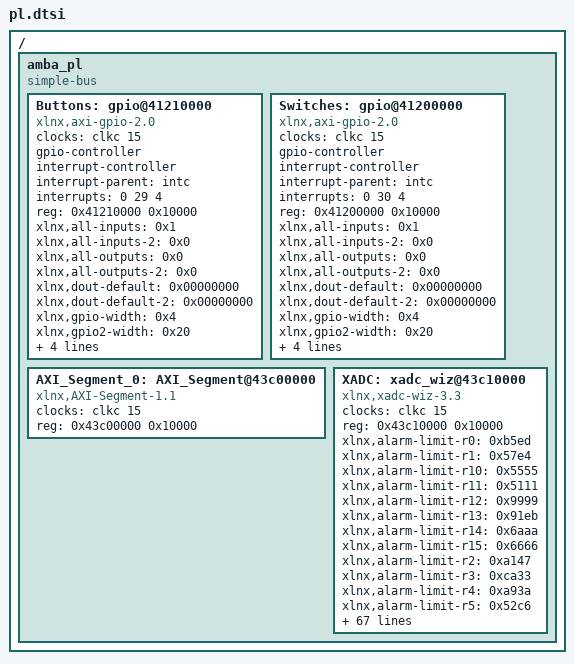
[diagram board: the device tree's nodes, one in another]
/*
 * CAUTION: This file is automatically generated by Xilinx.
 * Version:  
 * Today is: Sat Jan 26 14:19:15 2019
 */


/ {
	amba_pl: amba_pl {
		#address-cells = <1>;
		#size-cells = <1>;
		compatible = "simple-bus";
		ranges ;
		Buttons: gpio@41210000 {
			#gpio-cells = <3>;
			#interrupt-cells = <2>;
			clock-names = "s_axi_aclk";
			clocks = <&clkc 15>;
			compatible = "xlnx,axi-gpio-2.0", "xlnx,xps-gpio-1.00.a";
			gpio-controller ;
			interrupt-controller ;
			interrupt-names = "ip2intc_irpt";
			interrupt-parent = <&intc>;
			interrupts = <0 29 4>;
			reg = <0x41210000 0x10000>;
			xlnx,all-inputs = <0x1>;
			xlnx,all-inputs-2 = <0x0>;
			xlnx,all-outputs = <0x0>;
			xlnx,all-outputs-2 = <0x0>;
			xlnx,dout-default = <0x00000000>;
			xlnx,dout-default-2 = <0x00000000>;
			xlnx,gpio-width = <0x4>;
			xlnx,gpio2-width = <0x20>;
			xlnx,interrupt-present = <0x1>;
			xlnx,is-dual = <0x0>;
			xlnx,tri-default = <0xFFFFFFFF>;
			xlnx,tri-default-2 = <0xFFFFFFFF>;
		};
		Switches: gpio@41200000 {
			#gpio-cells = <3>;
			#interrupt-cells = <2>;
			clock-names = "s_axi_aclk";
			clocks = <&clkc 15>;
			compatible = "xlnx,axi-gpio-2.0", "xlnx,xps-gpio-1.00.a";
			gpio-controller ;
			interrupt-controller ;
			interrupt-names = "ip2intc_irpt";
			interrupt-parent = <&intc>;
			interrupts = <0 30 4>;
			reg = <0x41200000 0x10000>;
			xlnx,all-inputs = <0x1>;
			xlnx,all-inputs-2 = <0x0>;
			xlnx,all-outputs = <0x0>;
			xlnx,all-outputs-2 = <0x0>;
			xlnx,dout-default = <0x00000000>;
			xlnx,dout-default-2 = <0x00000000>;
			xlnx,gpio-width = <0x4>;
			xlnx,gpio2-width = <0x20>;
			xlnx,interrupt-present = <0x1>;
			xlnx,is-dual = <0x0>;
			xlnx,tri-default = <0xFFFFFFFF>;
			xlnx,tri-default-2 = <0xFFFFFFFF>;
		};
		AXI_Segment_0: AXI_Segment@43c00000 {
			clock-names = "s_axi_aclk";
			clocks = <&clkc 15>;
			compatible = "xlnx,AXI-Segment-1.1";
			reg = <0x43c00000 0x10000>;
		};
		XADC: xadc_wiz@43c10000 {
			clock-names = "s_axi_aclk";
			clocks = <&clkc 15>;
			compatible = "xlnx,xadc-wiz-3.3", "xlnx,axi-xadc-1.00.a";
			reg = <0x43c10000 0x10000>;
			xlnx,alarm-limit-r0 = <0xb5ed>;
			xlnx,alarm-limit-r1 = <0x57e4>;
			xlnx,alarm-limit-r10 = <0x5555>;
			xlnx,alarm-limit-r11 = <0x5111>;
			xlnx,alarm-limit-r12 = <0x9999>;
			xlnx,alarm-limit-r13 = <0x91eb>;
			xlnx,alarm-limit-r14 = <0x6aaa>;
			xlnx,alarm-limit-r15 = <0x6666>;
			xlnx,alarm-limit-r2 = <0xa147>;
			xlnx,alarm-limit-r3 = <0xca33>;
			xlnx,alarm-limit-r4 = <0xa93a>;
			xlnx,alarm-limit-r5 = <0x52c6>;
			xlnx,alarm-limit-r6 = <0x9555>;
			xlnx,alarm-limit-r7 = <0xae4e>;
			xlnx,alarm-limit-r8 = <0x5999>;
			xlnx,alarm-limit-r9 = <0x5111>;
			xlnx,configuration-r0 = <0x0>;
			xlnx,configuration-r1 = <0x21a0>;
			xlnx,configuration-r2 = <0x400>;
			xlnx,dclk-frequency = <0x64>;
			xlnx,external-mux = "none";
			xlnx,external-mux-channel = "VP_VN";
			xlnx,external-muxaddr-enable = <0x0>;
			xlnx,fifo-depth = <0x7>;
			xlnx,has-axi = <0x1>;
			xlnx,has-axi4stream = <0x0>;
			xlnx,has-busy = <0x1>;
			xlnx,has-channel = <0x1>;
			xlnx,has-convst = <0x0>;
			xlnx,has-convstclk = <0x0>;
			xlnx,has-dclk = <0x1>;
			xlnx,has-drp = <0x0>;
			xlnx,has-eoc = <0x1>;
			xlnx,has-eos = <0x1>;
			xlnx,has-external-mux = <0x0>;
			xlnx,has-jtagbusy = <0x0>;
			xlnx,has-jtaglocked = <0x0>;
			xlnx,has-jtagmodified = <0x0>;
			xlnx,has-ot-alarm = <0x1>;
			xlnx,has-reset = <0x0>;
			xlnx,has-temp-bus = <0x0>;
			xlnx,has-user-temp-alarm = <0x1>;
			xlnx,has-vbram-alarm = <0x0>;
			xlnx,has-vccaux-alarm = <0x1>;
			xlnx,has-vccddro-alarm = <0x1>;
			xlnx,has-vccint-alarm = <0x1>;
			xlnx,has-vccpaux-alarm = <0x1>;
			xlnx,has-vccpint-alarm = <0x1>;
			xlnx,has-vn = <0x1>;
			xlnx,has-vp = <0x1>;
			xlnx,include-intr = <0x1>;
			xlnx,sampling-rate = "961538.4615384615";
			xlnx,sequence-r0 = <0x3901>;
			xlnx,sequence-r1 = <0xc0c0>;
			xlnx,sequence-r2 = <0x900>;
			xlnx,sequence-r3 = <0xc0c0>;
			xlnx,sequence-r4 = <0x800>;
			xlnx,sequence-r5 = <0xc0c0>;
			xlnx,sequence-r6 = <0x800>;
			xlnx,sequence-r7 = <0xc0c0>;
			xlnx,sim-file-name = "design";
			xlnx,sim-file-rel-path = "./";
			xlnx,sim-file-sel = "Default";
			xlnx,vaux0 = <0x0>;
			xlnx,vaux1 = <0x0>;
			xlnx,vaux10 = <0x0>;
			xlnx,vaux11 = <0x0>;
			xlnx,vaux12 = <0x0>;
			xlnx,vaux13 = <0x0>;
			xlnx,vaux14 = <0x1>;
			xlnx,vaux15 = <0x1>;
			xlnx,vaux2 = <0x0>;
			xlnx,vaux3 = <0x0>;
			xlnx,vaux4 = <0x0>;
			xlnx,vaux5 = <0x0>;
			xlnx,vaux6 = <0x1>;
			xlnx,vaux7 = <0x1>;
			xlnx,vaux8 = <0x0>;
			xlnx,vaux9 = <0x0>;
		};
	};
};
